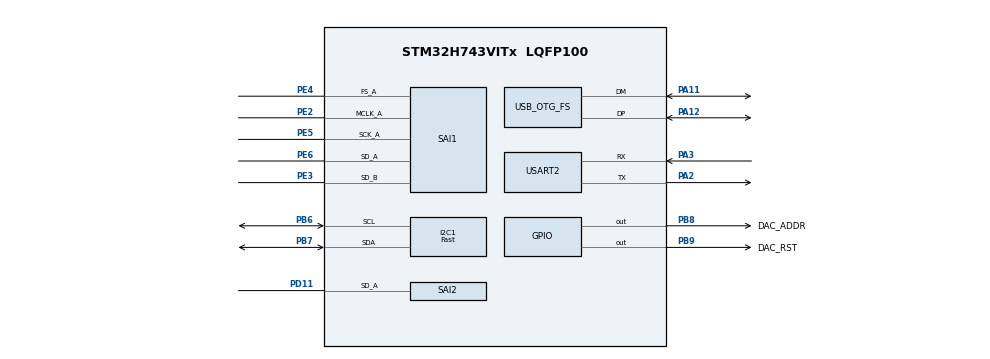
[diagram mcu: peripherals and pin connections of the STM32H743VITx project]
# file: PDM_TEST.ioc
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CORTEX_M7.AccessPermission-Cortex_Memory_Protection_Unit_Region0_Settings=MPU_REGION_FULL_ACCESS
CORTEX_M7.AccessPermission-Cortex_Memory_Protection_Unit_Region1_Settings=MPU_REGION_FULL_ACCESS
CORTEX_M7.BaseAddress-Cortex_Memory_Protection_Unit_Region0_Settings=0x24000000
CORTEX_M7.BaseAddress-Cortex_Memory_Protection_Unit_Region1_Settings=0x38000000
CORTEX_M7.CPU_DCache=Enabled
CORTEX_M7.CPU_ICache=Enabled
CORTEX_M7.Enable-Cortex_Memory_Protection_Unit_Region0_Settings=MPU_REGION_ENABLE
CORTEX_M7.Enable-Cortex_Memory_Protection_Unit_Region1_Settings=MPU_REGION_ENABLE
CORTEX_M7.IsBufferable-Cortex_Memory_Protection_Unit_Region0_Settings=MPU_ACCESS_BUFFERABLE
CORTEX_M7.IsCacheable-Cortex_Memory_Protection_Unit_Region0_Settings=MPU_ACCESS_CACHEABLE
CORTEX_M7.IsCacheable-Cortex_Memory_Protection_Unit_Region1_Settings=MPU_ACCESS_CACHEABLE
CORTEX_M7.IsShareable-Cortex_Memory_Protection_Unit_Region0_Settings=MPU_ACCESS_NOT_SHAREABLE
CORTEX_M7.IsShareable-Cortex_Memory_Protection_Unit_Region1_Settings=MPU_ACCESS_SHAREABLE
CORTEX_M7.MPU_Control=MPU_PRIVILEGED_DEFAULT
CORTEX_M7.Size-Cortex_Memory_Protection_Unit_Region0_Settings=MPU_REGION_SIZE_512KB
CORTEX_M7.Size-Cortex_Memory_Protection_Unit_Region1_Settings=MPU_REGION_SIZE_64KB
CORTEX_M7.TypeExtField-Cortex_Memory_Protection_Unit_Region0_Settings=MPU_TEX_LEVEL1
CORTEX_M7.TypeExtField-Cortex_Memory_Protection_Unit_Region1_Settings=MPU_TEX_LEVEL1
Dma.Request0=SAI1_A
Dma.Request1=SAI1_B
Dma.Request2=SAI2_A
Dma.Request3=USART2_RX
Dma.Request4=USART2_TX
Dma.SAI1_A.0.Direction=DMA_MEMORY_TO_PERIPH
Dma.SAI1_A.0.EventEnable=DISABLE
Dma.SAI1_A.0.FIFOMode=DMA_FIFOMODE_ENABLE
Dma.SAI1_A.0.FIFOThreshold=DMA_FIFO_THRESHOLD_FULL
Dma.SAI1_A.0.Instance=DMA1_Stream0
Dma.SAI1_A.0.MemBurst=DMA_MBURST_SINGLE
Dma.SAI1_A.0.MemDataAlignment=DMA_MDATAALIGN_WORD
Dma.SAI1_A.0.MemInc=DMA_MINC_ENABLE
Dma.SAI1_A.0.Mode=DMA_CIRCULAR
Dma.SAI1_A.0.PeriphBurst=DMA_PBURST_SINGLE
Dma.SAI1_A.0.PeriphDataAlignment=DMA_PDATAALIGN_WORD
Dma.SAI1_A.0.PeriphInc=DMA_PINC_DISABLE
Dma.SAI1_A.0.Polarity=HAL_DMAMUX_REQ_GEN_RISING
Dma.SAI1_A.0.Priority=DMA_PRIORITY_HIGH
Dma.SAI1_A.0.RequestNumber=1
Dma.SAI1_A.0.SignalID=NONE
Dma.SAI1_A.0.SyncEnable=DISABLE
Dma.SAI1_A.0.SyncPolarity=HAL_DMAMUX_SYNC_NO_EVENT
Dma.SAI1_A.0.SyncRequestNumber=1
Dma.SAI1_A.0.SyncSignalID=NONE
Dma.SAI1_B.1.Direction=DMA_PERIPH_TO_MEMORY
Dma.SAI1_B.1.EventEnable=DISABLE
Dma.SAI1_B.1.FIFOMode=DMA_FIFOMODE_ENABLE
Dma.SAI1_B.1.FIFOThreshold=DMA_FIFO_THRESHOLD_FULL
Dma.SAI1_B.1.Instance=DMA2_Stream0
Dma.SAI1_B.1.MemBurst=DMA_MBURST_SINGLE
Dma.SAI1_B.1.MemDataAlignment=DMA_MDATAALIGN_WORD
Dma.SAI1_B.1.MemInc=DMA_MINC_ENABLE
Dma.SAI1_B.1.Mode=DMA_CIRCULAR
Dma.SAI1_B.1.PeriphBurst=DMA_PBURST_SINGLE
Dma.SAI1_B.1.PeriphDataAlignment=DMA_PDATAALIGN_WORD
Dma.SAI1_B.1.PeriphInc=DMA_PINC_DISABLE
Dma.SAI1_B.1.Polarity=HAL_DMAMUX_REQ_GEN_RISING
Dma.SAI1_B.1.Priority=DMA_PRIORITY_HIGH
Dma.SAI1_B.1.RequestNumber=1
Dma.SAI1_B.1.SignalID=NONE
Dma.SAI1_B.1.SyncEnable=DISABLE
Dma.SAI1_B.1.SyncPolarity=HAL_DMAMUX_SYNC_NO_EVENT
Dma.SAI1_B.1.SyncRequestNumber=1
Dma.SAI1_B.1.SyncSignalID=NONE
Dma.SAI2_A.2.Direction=DMA_PERIPH_TO_MEMORY
Dma.SAI2_A.2.EventEnable=DISABLE
Dma.SAI2_A.2.FIFOMode=DMA_FIFOMODE_ENABLE
Dma.SAI2_A.2.FIFOThreshold=DMA_FIFO_THRESHOLD_FULL
Dma.SAI2_A.2.Instance=DMA1_Stream4
Dma.SAI2_A.2.MemBurst=DMA_MBURST_SINGLE
Dma.SAI2_A.2.MemDataAlignment=DMA_MDATAALIGN_WORD
Dma.SAI2_A.2.MemInc=DMA_MINC_ENABLE
Dma.SAI2_A.2.Mode=DMA_CIRCULAR
Dma.SAI2_A.2.PeriphBurst=DMA_PBURST_SINGLE
Dma.SAI2_A.2.PeriphDataAlignment=DMA_PDATAALIGN_WORD
Dma.SAI2_A.2.PeriphInc=DMA_PINC_DISABLE
Dma.SAI2_A.2.Polarity=HAL_DMAMUX_REQ_GEN_RISING
Dma.SAI2_A.2.Priority=DMA_PRIORITY_HIGH
Dma.SAI2_A.2.RequestNumber=1
Dma.SAI2_A.2.SignalID=NONE
Dma.SAI2_A.2.SyncEnable=DISABLE
Dma.SAI2_A.2.SyncPolarity=HAL_DMAMUX_SYNC_NO_EVENT
Dma.SAI2_A.2.SyncRequestNumber=1
Dma.SAI2_A.2.SyncSignalID=NONE
Dma.USART2_RX.3.Direction=DMA_PERIPH_TO_MEMORY
Dma.USART2_RX.3.EventEnable=DISABLE
Dma.USART2_RX.3.FIFOMode=DMA_FIFOMODE_DISABLE
Dma.USART2_RX.3.Instance=DMA1_Stream1
Dma.USART2_RX.3.MemDataAlignment=DMA_MDATAALIGN_BYTE
Dma.USART2_RX.3.MemInc=DMA_MINC_ENABLE
Dma.USART2_RX.3.Mode=DMA_NORMAL
Dma.USART2_RX.3.PeriphDataAlignment=DMA_PDATAALIGN_BYTE
Dma.USART2_RX.3.PeriphInc=DMA_PINC_DISABLE
Dma.USART2_RX.3.Polarity=HAL_DMAMUX_REQ_GEN_RISING
Dma.USART2_RX.3.Priority=DMA_PRIORITY_LOW
Dma.USART2_RX.3.RequestNumber=1
Dma.USART2_RX.3.SignalID=NONE
Dma.USART2_RX.3.SyncEnable=DISABLE
Dma.USART2_RX.3.SyncPolarity=HAL_DMAMUX_SYNC_NO_EVENT
Dma.USART2_RX.3.SyncRequestNumber=1
Dma.USART2_RX.3.SyncSignalID=NONE
Dma.USART2_TX.4.Direction=DMA_MEMORY_TO_PERIPH
Dma.USART2_TX.4.EventEnable=DISABLE
Dma.USART2_TX.4.FIFOMode=DMA_FIFOMODE_DISABLE
Dma.USART2_TX.4.Instance=DMA1_Stream2
Dma.USART2_TX.4.MemDataAlignment=DMA_MDATAALIGN_BYTE
Dma.USART2_TX.4.MemInc=DMA_MINC_ENABLE
Dma.USART2_TX.4.Mode=DMA_NORMAL
Dma.USART2_TX.4.PeriphDataAlignment=DMA_PDATAALIGN_BYTE
Dma.USART2_TX.4.PeriphInc=DMA_PINC_DISABLE
Dma.USART2_TX.4.Polarity=HAL_DMAMUX_REQ_GEN_RISING
Dma.USART2_TX.4.Priority=DMA_PRIORITY_LOW
Dma.USART2_TX.4.RequestNumber=1
Dma.USART2_TX.4.SignalID=NONE
Dma.USART2_TX.4.SyncEnable=DISABLE
Dma.USART2_TX.4.SyncPolarity=HAL_DMAMUX_SYNC_NO_EVENT
Dma.USART2_TX.4.SyncRequestNumber=1
Dma.USART2_TX.4.SyncSignalID=NONE
I2C1.CustomTiming=Enabled
I2C1.I2C_Speed_Mode=I2C_Fast
I2C1.Timing=0x10C0ECFF
Mcu.Family=STM32H7
Mcu.Name=STM32H743VITx
Mcu.Package=LQFP100
NVIC.DMA1_Stream0_IRQn=true\:0\:0\:false\:false\:true\:false\:true
NVIC.DMA1_Stream1_IRQn=true\:0\:0\:false\:false\:true\:false\:true
NVIC.DMA1_Stream2_IRQn=true\:0\:0\:false\:false\:true\:false\:true
NVIC.DMA1_Stream4_IRQn=true\:0\:0\:false\:false\:true\:false\:true
NVIC.DMA2_Stream0_IRQn=true\:0\:0\:false\:false\:true\:false\:true
NVIC.PriorityGroup=NVIC_PRIORITYGROUP_4
NVIC.USART2_IRQn=true\:0\:0\:false\:false\:true\:true\:true
PA11.Mode=Device_Only
PA11.Signal=USB_OTG_FS_DM
PA12.Mode=Device_Only
PA12.Signal=USB_OTG_FS_DP
PA13\ (JTMS/SWDIO).Mode=Serial_Wire
PA13\ (JTMS/SWDIO).Signal=DEBUG_JTMS-SWDIO
PA14\ (JTCK/SWCLK).Mode=Serial_Wire
PA14\ (JTCK/SWCLK).Signal=DEBUG_JTCK-SWCLK
PA2.Mode=Asynchronous
PA2.Signal=USART2_TX
PA3.Mode=Asynchronous
PA3.Signal=USART2_RX
PB6.GPIO_PuPd=GPIO_PULLUP
PB6.Mode=I2C
PB6.Signal=I2C1_SCL
PB7.GPIO_PuPd=GPIO_PULLUP
PB7.Mode=I2C
PB7.Signal=I2C1_SDA
PB8.GPIO_Label=DAC_ADDR
PB8.Signal=GPIO_Output
PB9.GPIO_Label=DAC_RST
PB9.Signal=GPIO_Output
PC14-OSC32_IN\ (OSC32_IN).Mode=LSE-External-Oscillator
PC14-OSC32_IN\ (OSC32_IN).Signal=RCC_OSC32_IN
PC15-OSC32_OUT\ (OSC32_OUT).Mode=LSE-External-Oscillator
PC15-OSC32_OUT\ (OSC32_OUT).Signal=RCC_OSC32_OUT
PD11.GPIO_Speed=GPIO_SPEED_FREQ_LOW
PD11.Mode=SAI_A_SyncSlave
PD11.Signal=SAI2_SD_A
PE2.Mode=SAI_A_MasterWithClock
PE2.Signal=SAI1_MCLK_A
PE3.GPIO_Speed=GPIO_SPEED_FREQ_LOW
PE3.Mode=SAI_B_SyncSlave
PE3.Signal=SAI1_SD_B
PE4.GPIO_Speed=GPIO_SPEED_FREQ_LOW
PE4.Mode=SAI_A_MasterWithClock
PE4.Signal=SAI1_FS_A
PE5.GPIO_Speed=GPIO_SPEED_FREQ_LOW
PE5.Mode=SAI_A_MasterWithClock
PE5.Signal=SAI1_SCK_A
PE6.GPIO_Speed=GPIO_SPEED_FREQ_LOW
PE6.Mode=SAI_A_MasterWithClock
PE6.Signal=SAI1_SD_A
PH0-OSC_IN\ (PH0).Mode=HSE-External-Oscillator
PH0-OSC_IN\ (PH0).Signal=RCC_OSC_IN
PH1-OSC_OUT\ (PH1).Mode=HSE-External-Oscillator
PH1-OSC_OUT\ (PH1).Signal=RCC_OSC_OUT
ProjectManager.HeapSize=0xC000
ProjectManager.StackSize=0xA000
ProjectManager.TargetToolchain=MDK-ARM V5.27
RCC.ADCFreq_Value=106500000
RCC.APB1Freq_Value=120000000
RCC.APB2Freq_Value=120000000
RCC.APB3Freq_Value=120000000
RCC.APB4Freq_Value=120000000
RCC.CortexFreq_Value=480000000
RCC.D1PPRE=RCC_APB3_DIV2
RCC.D2PPRE1=RCC_APB1_DIV2
RCC.D2PPRE2=RCC_APB2_DIV2
RCC.D3PPRE=RCC_APB4_DIV2
RCC.DIVM1=5
RCC.DIVM2=25
RCC.DIVM3=25
RCC.DIVN1=192
RCC.DIVN2=213
RCC.DIVN3=256
RCC.DIVP3=125
RCC.HCLKFreq_Value=240000000
RCC.HPRE=RCC_HCLK_DIV2
RCC.PLL2FRACN=0
RCC.PLL3FRACN=0
RCC.PLLFRACN=0
RCC.PLLSourceVirtual=RCC_PLLSOURCE_HSE
RCC.SAI1CLockSelection=RCC_SAI1CLKSOURCE_PLL2
RCC.SAI23CLockSelection=RCC_SAI23CLKSOURCE_PLL2
RCC.SPI123CLockSelection=RCC_SPI123CLKSOURCE_PLL3
RCC.SYSCLKFreq_VALUE=480000000
RCC.SYSCLKSource=RCC_SYSCLKSOURCE_PLLCLK
RCC.USBCLockSelection=RCC_USBCLKSOURCE_HSI48
RCC.USBFreq_Value=48000000
SAI1.AudioFrequency-SAI_A_MasterWithClock=SAI_AUDIO_FREQUENCY_16K
SAI1.BasicDataSize-SAI_A_MasterWithClock=SAI_PROTOCOL_DATASIZE_24BIT
SAI1.BasicDataSize-SAI_B_SyncSlave=SAI_PROTOCOL_DATASIZE_24BIT
SAI1.BasicProtocol-SAI_B_SyncSlave=SAI_I2S_STANDARD
SAI1.ErrorAudioFreq-SAI_A_MasterWithClock=0.0 %
SAI1.FIFOThreshold-SAI_B_SyncSlave=SAI_FIFOTHRESHOLD_EMPTY
SAI1.InitProtocol-SAI_A_MasterWithClock=Enable
SAI1.InitProtocol-SAI_B_SyncSlave=Enable
SAI1.Instance-SAI_A_MasterWithClock=SAI$Index_Block_A
SAI1.Instance-SAI_B_SyncSlave=SAI$Index_Block_B
SAI1.MClockEnable=SAI_MASTERCLOCK_ENABLE
SAI1.OutputDrive-SAI_A_MasterWithClock=SAI_OUTPUTDRIVE_ENABLE
SAI1.OutputDrive-SAI_B_SyncSlave=SAI_OUTPUTDRIVE_ENABLE
SAI1.RealAudioFreq-SAI_A_MasterWithClock=16.0 KHz
SAI1.SynchroExt=SAI_SYNCEXT_OUTBLOCKA_ENABLE
SAI1.VirtualMode-SAI_A_MasterWithClock=VM_MASTER
SAI1.VirtualMode-SAI_B_SyncSlave=VM_SLAVE
SAI1.VirtualProtocol-SAI_A_BASIC=VM_BASIC_PROTOCOL
SAI1.VirtualProtocol-SAI_B_BASIC=VM_BASIC_PROTOCOL
SAI2.BasicDataSize-SAI_A_SyncSlave=SAI_PROTOCOL_DATASIZE_24BIT
SAI2.BasicProtocol-SAI_A_SyncSlave=SAI_I2S_STANDARD
SAI2.FIFOThreshold-SAI_A_SyncSlave=SAI_FIFOTHRESHOLD_EMPTY
SAI2.InitProtocol-SAI_A_SyncSlave=Enable
SAI2.Instance-SAI_A_SyncSlave=SAI$Index_Block_A
SAI2.OutputDrive-SAI_A_SyncSlave=SAI_OUTPUTDRIVE_ENABLE
SAI2.Synchro_A=SAI_SYNCHRONOUS_EXT_SAI1
SAI2.VirtualMode-SAI_A_SyncSlave=VM_SLAVE
SAI2.VirtualProtocol-SAI_A_BASIC=VM_BASIC_PROTOCOL
USART2.VirtualMode-Asynchronous=VM_ASYNC
USB_OTG_FS.VirtualMode=Device_Only
VP_SAI1_VP_$IpInstance_SAIA_SAI_BASIC.Mode=SAI_A_BASIC
VP_SAI1_VP_$IpInstance_SAIB_SAI_BASIC.Mode=SAI_B_BASIC
VP_SAI1_VP_$IpInstance_SYNCHRO_EXTERNAL.Mode=SynchroExternal
VP_SAI2_VP_$IpInstance_SAIA_SAI_BASIC.Mode=SAI_A_BASIC
board=custom

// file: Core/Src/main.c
/* USER CODE BEGIN Header */
/**
  ******************************************************************************
  * @file           : main.c
  * @brief          : Main program body
  ******************************************************************************
  * @attention
  *
  * <h2><center>&copy; Copyright (c) 2021 STMicroelectronics.
  * All rights reserved.</center></h2>
  *
  * This software component is licensed by ST under Ultimate Liberty license
  * SLA0044, the "License"; You may not use this file except in compliance with
  * the License. You may obtain a copy of the License at:
  *                             www.st.com/SLA0044
  *
  ******************************************************************************
  */
/* USER CODE END Header */
#include "main.h"
#include "dma.h"
#include "i2c.h"
#include "sai.h"
#include "usart.h"
#include "usb_otg.h"
#include "gpio.h"

void SystemClock_Config(void);
void PeriphCommonClock_Config(void);
static void MPU_Config(void);

int main(void)
{

  /* MPU Configuration--------------------------------------------------------*/
  MPU_Config();

  /* Enable I-Cache---------------------------------------------------------*/
  SCB_EnableICache();

  /* Enable D-Cache---------------------------------------------------------*/
  SCB_EnableDCache();

  /* MCU Configuration--------------------------------------------------------*/

  /* Reset of all peripherals, Initializes the Flash interface and the Systick. */
  HAL_Init();

  /* Configure the system clock */
  SystemClock_Config();

/* Configure the peripherals common clocks */
  PeriphCommonClock_Config();

  /* Initialize all configured peripherals */
  MX_GPIO_Init();
  MX_DMA_Init();
  MX_SAI1_Init();
  MX_USART2_UART_Init();
//  MX_USB_OTG_FS_PCD_Init();
  MX_SAI2_Init();
  MX_I2C1_Init();
  /* USER CODE BEGIN 2 */
  User_Main_Task_Init();
  /* USER CODE END 2 */

  /* Infinite loop */
  while (1)
  {

    /* USER CODE BEGIN 3 */
    User_Main_Task_Process_Loop();
  }
  /* USER CODE END 3 */
}

void SystemClock_Config(void)
{
  RCC_OscInitTypeDef RCC_OscInitStruct = {0};
  RCC_ClkInitTypeDef RCC_ClkInitStruct = {0};

  /** Supply configuration update enable
  */
  HAL_PWREx_ConfigSupply(PWR_LDO_SUPPLY);
  /** Configure the main internal regulator output voltage
  */
  __HAL_PWR_VOLTAGESCALING_CONFIG(PWR_REGULATOR_VOLTAGE_SCALE0);

  while(!__HAL_PWR_GET_FLAG(PWR_FLAG_VOSRDY)) {}
  /** Macro to configure the PLL clock source
  */
  __HAL_RCC_PLL_PLLSOURCE_CONFIG(RCC_PLLSOURCE_HSE);
  /** Initializes the RCC Oscillators according to the specified parameters
  * in the RCC_OscInitTypeDef structure.
  */
  RCC_OscInitStruct.OscillatorType = RCC_OSCILLATORTYPE_HSI48|RCC_OSCILLATORTYPE_HSE;
  RCC_OscInitStruct.HSEState = RCC_HSE_ON;
  RCC_OscInitStruct.HSI48State = RCC_HSI48_ON;
  RCC_OscInitStruct.PLL.PLLState = RCC_PLL_ON;
  RCC_OscInitStruct.PLL.PLLSource = RCC_PLLSOURCE_HSE;
  RCC_OscInitStruct.PLL.PLLM = 5;
  RCC_OscInitStruct.PLL.PLLN = 192;
  RCC_OscInitStruct.PLL.PLLP = 2;
  RCC_OscInitStruct.PLL.PLLQ = 2;
  RCC_OscInitStruct.PLL.PLLR = 2;
  RCC_OscInitStruct.PLL.PLLRGE = RCC_PLL1VCIRANGE_2;
  RCC_OscInitStruct.PLL.PLLVCOSEL = RCC_PLL1VCOWIDE;
  RCC_OscInitStruct.PLL.PLLFRACN = 0;
  if (HAL_RCC_OscConfig(&RCC_OscInitStruct) != HAL_OK)
  {
    Error_Handler();
  }
  /** Initializes the CPU, AHB and APB buses clocks
  */
  RCC_ClkInitStruct.ClockType = RCC_CLOCKTYPE_HCLK|RCC_CLOCKTYPE_SYSCLK
                              |RCC_CLOCKTYPE_PCLK1|RCC_CLOCKTYPE_PCLK2
                              |RCC_CLOCKTYPE_D3PCLK1|RCC_CLOCKTYPE_D1PCLK1;
  RCC_ClkInitStruct.SYSCLKSource = RCC_SYSCLKSOURCE_PLLCLK;
  RCC_ClkInitStruct.SYSCLKDivider = RCC_SYSCLK_DIV1;
  RCC_ClkInitStruct.AHBCLKDivider = RCC_HCLK_DIV2;
  RCC_ClkInitStruct.APB3CLKDivider = RCC_APB3_DIV2;
  RCC_ClkInitStruct.APB1CLKDivider = RCC_APB1_DIV2;
  RCC_ClkInitStruct.APB2CLKDivider = RCC_APB2_DIV2;
  RCC_ClkInitStruct.APB4CLKDivider = RCC_APB4_DIV2;

  if (HAL_RCC_ClockConfig(&RCC_ClkInitStruct, FLASH_LATENCY_4) != HAL_OK)
  {
    Error_Handler();
  }
}

void PeriphCommonClock_Config(void)
{
  RCC_PeriphCLKInitTypeDef PeriphClkInitStruct = {0};

  /** Initializes the peripherals clock
  */
  PeriphClkInitStruct.PeriphClockSelection = RCC_PERIPHCLK_SAI1|RCC_PERIPHCLK_SAI2;
  PeriphClkInitStruct.PLL2.PLL2M = 25;
  PeriphClkInitStruct.PLL2.PLL2N = 213;
  PeriphClkInitStruct.PLL2.PLL2P = 2;
  PeriphClkInitStruct.PLL2.PLL2Q = 2;
  PeriphClkInitStruct.PLL2.PLL2R = 2;
  PeriphClkInitStruct.PLL2.PLL2RGE = RCC_PLL2VCIRANGE_0;
  PeriphClkInitStruct.PLL2.PLL2VCOSEL = RCC_PLL2VCOWIDE;
  PeriphClkInitStruct.PLL2.PLL2FRACN = 0;
  PeriphClkInitStruct.Sai1ClockSelection = RCC_SAI1CLKSOURCE_PLL2;
  PeriphClkInitStruct.Sai23ClockSelection = RCC_SAI23CLKSOURCE_PLL2;
  if (HAL_RCCEx_PeriphCLKConfig(&PeriphClkInitStruct) != HAL_OK)
  {
    Error_Handler();
  }
}

/* MPU Configuration */

void MPU_Config(void)
{
  MPU_Region_InitTypeDef MPU_InitStruct = {0};

  /* Disables the MPU */
  HAL_MPU_Disable();
  /** Initializes and configures the Region and the memory to be protected
  */
  MPU_InitStruct.Enable = MPU_REGION_ENABLE;
  MPU_InitStruct.Number = MPU_REGION_NUMBER0;
  MPU_InitStruct.BaseAddress = 0x24000000;
  MPU_InitStruct.Size = MPU_REGION_SIZE_512KB;
  MPU_InitStruct.SubRegionDisable = 0x0;
  MPU_InitStruct.TypeExtField = MPU_TEX_LEVEL1;
  MPU_InitStruct.AccessPermission = MPU_REGION_FULL_ACCESS;
  MPU_InitStruct.DisableExec = MPU_INSTRUCTION_ACCESS_ENABLE;
  MPU_InitStruct.IsShareable = MPU_ACCESS_NOT_SHAREABLE;
  MPU_InitStruct.IsCacheable = MPU_ACCESS_CACHEABLE;
  MPU_InitStruct.IsBufferable = MPU_ACCESS_BUFFERABLE;

  HAL_MPU_ConfigRegion(&MPU_InitStruct);
  /** Initializes and configures the Region and the memory to be protected
  */
  MPU_InitStruct.Number = MPU_REGION_NUMBER1;
  MPU_InitStruct.BaseAddress = 0x38000000;
  MPU_InitStruct.Size = MPU_REGION_SIZE_64KB;
  MPU_InitStruct.IsShareable = MPU_ACCESS_SHAREABLE;
  MPU_InitStruct.IsBufferable = MPU_ACCESS_NOT_BUFFERABLE;

  HAL_MPU_ConfigRegion(&MPU_InitStruct);
  /* Enables the MPU */
  HAL_MPU_Enable(MPU_PRIVILEGED_DEFAULT);

}

void Error_Handler(void)
{
  __disable_irq();
  while (1)
  {
  }
}

/************************ (C) COPYRIGHT STMicroelectronics *****END OF FILE****/
